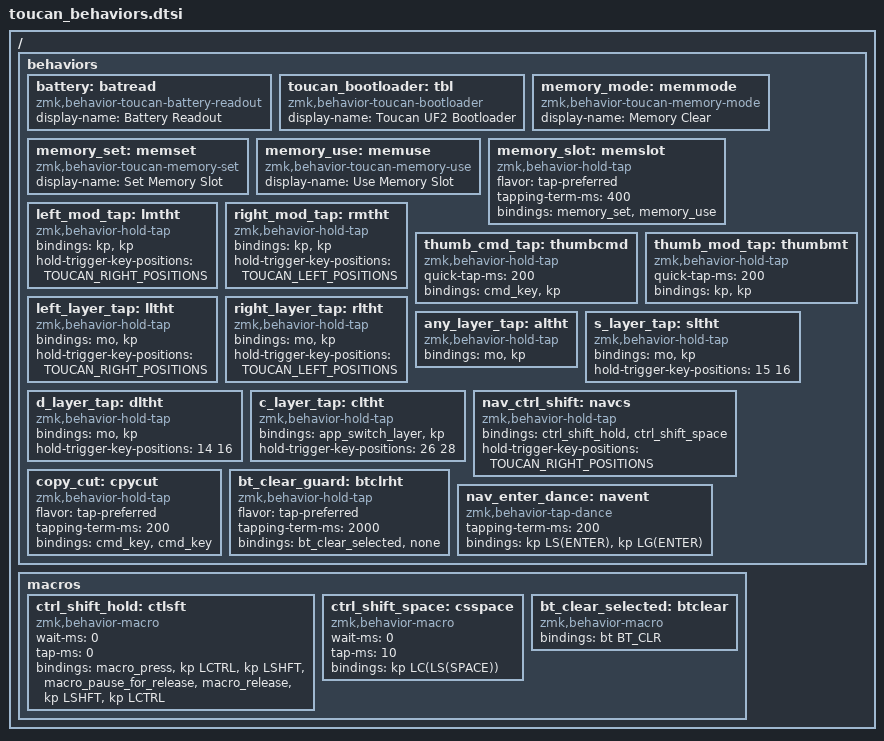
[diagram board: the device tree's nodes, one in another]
/* Custom reusable behaviors shared by both halves. */

#include <toucan_layers.dtsi>

/* One rollover policy for all typing-facing hold-taps, including NAV F.
 * Position filters and thumb repeat are configured per behavior below.
 * Copy/cut, memory replacement, and Bluetooth clear keep deliberate-hold rules. */
#define TOUCAN_TYPING_HOLD_TAP_POLICY                                                           \
    flavor = "balanced";                                                                       \
    tapping-term-ms = <200>;                                                                    \
    require-prior-idle-ms = <125>;

/* Physical positions on the opposite side of each hand's tap-hold keys. */
#define TOUCAN_LEFT_POSITIONS                                                                   \
    0 1 2 3 4 5 12 13 14 15 16 17 24 25 26 27 28 29 36 37 38
#define TOUCAN_RIGHT_POSITIONS                                                                  \
    6 7 8 9 10 11 18 19 20 21 22 23 30 31 32 33 34 35 39 40 41

/ {
    behaviors {
        /* Short node names are required for behaviors used from peripherals. */
        battery: batread {
            compatible = "zmk,behavior-toucan-battery-readout";
            #binding-cells = <0>;
            display-name = "Battery Readout";
        };

        toucan_bootloader: tbl {
            compatible = "zmk,behavior-toucan-bootloader";
            #binding-cells = <0>;
            display-name = "Toucan UF2 Bootloader";
        };

        memory_mode: memmode {
            compatible = "zmk,behavior-toucan-memory-mode";
            #binding-cells = <0>;
            display-name = "Memory Clear";
        };

        memory_set: memset {
            compatible = "zmk,behavior-toucan-memory-set";
            #binding-cells = <1>;
            display-name = "Set Memory Slot";
        };

        memory_use: memuse {
            compatible = "zmk,behavior-toucan-memory-use";
            #binding-cells = <1>;
            display-name = "Use Memory Slot";
        };

        /* Tap a slot to play it; hold it deliberately to replace it. */
        memory_slot: memslot {
            compatible = "zmk,behavior-hold-tap";
            #binding-cells = <2>;
            flavor = "tap-preferred";
            tapping-term-ms = <400>;
            bindings = <&memory_set>, <&memory_use>;
        };

        /* Opposite-hand modifier chords, with the shared typing-roll guard. */
        left_mod_tap: lmtht {
            compatible = "zmk,behavior-hold-tap";
            #binding-cells = <2>;
            TOUCAN_TYPING_HOLD_TAP_POLICY
            bindings = <&kp>, <&kp>;
            hold-trigger-key-positions = <TOUCAN_RIGHT_POSITIONS>;
        };

        right_mod_tap: rmtht {
            compatible = "zmk,behavior-hold-tap";
            #binding-cells = <2>;
            TOUCAN_TYPING_HOLD_TAP_POLICY
            bindings = <&kp>, <&kp>;
            hold-trigger-key-positions = <TOUCAN_LEFT_POSITIONS>;
        };

        /* Tab on tap; platform-aware Command/Control on a deliberate hold. */
        thumb_cmd_tap: thumbcmd {
            compatible = "zmk,behavior-hold-tap";
            #binding-cells = <2>;
            TOUCAN_TYPING_HOLD_TAP_POLICY
            quick-tap-ms = <200>;
            bindings = <&cmd_key>, <&kp>;
        };

        /* Enter on tap; Option/Alt on hold, with tap-then-hold repeat. */
        thumb_mod_tap: thumbmt {
            compatible = "zmk,behavior-hold-tap";
            #binding-cells = <2>;
            TOUCAN_TYPING_HOLD_TAP_POLICY
            quick-tap-ms = <200>;
            bindings = <&kp>, <&kp>;
        };

        /* A and semicolon hold SYM only for opposite-hand chords. */
        left_layer_tap: lltht {
            compatible = "zmk,behavior-hold-tap";
            #binding-cells = <2>;
            TOUCAN_TYPING_HOLD_TAP_POLICY
            bindings = <&mo>, <&kp>;
            hold-trigger-key-positions = <TOUCAN_RIGHT_POSITIONS>;
        };

        right_layer_tap: rltht {
            compatible = "zmk,behavior-hold-tap";
            #binding-cells = <2>;
            TOUCAN_TYPING_HOLD_TAP_POLICY
            bindings = <&mo>, <&kp>;
            hold-trigger-key-positions = <TOUCAN_LEFT_POSITIONS>;
        };

        /* Q and P use release order to distinguish NAV chords from rolls. */
        any_layer_tap: altht {
            compatible = "zmk,behavior-hold-tap";
            #binding-cells = <2>;
            TOUCAN_TYPING_HOLD_TAP_POLICY
            bindings = <&mo>, <&kp>;
        };

        /* S holds CLIP only for D/F; D holds EDIT only for S/F. Release the
         * leader first for a typing roll, or the target first for a chord. */
        s_layer_tap: sltht {
            compatible = "zmk,behavior-hold-tap";
            #binding-cells = <2>;
            TOUCAN_TYPING_HOLD_TAP_POLICY
            bindings = <&mo>, <&kp>;
            hold-trigger-key-positions = <15 16>;
        };

        d_layer_tap: dltht {
            compatible = "zmk,behavior-hold-tap";
            #binding-cells = <2>;
            TOUCAN_TYPING_HOLD_TAP_POLICY
            bindings = <&mo>, <&kp>;
            hold-trigger-key-positions = <14 16>;
        };

        /* C holds APP only for X/V, with the same rollover policy as S/D. */
        c_layer_tap: cltht {
            compatible = "zmk,behavior-hold-tap";
            #binding-cells = <2>;
            TOUCAN_TYPING_HOLD_TAP_POLICY
            bindings = <&app_switch_layer>, <&kp>;
            hold-trigger-key-positions = <26 28>;
        };

        /* NAV F: hold Ctrl+Shift; tap Ctrl+Shift+Space. */
        nav_ctrl_shift: navcs {
            compatible = "zmk,behavior-hold-tap";
            #binding-cells = <2>;
            TOUCAN_TYPING_HOLD_TAP_POLICY
            bindings = <&ctrl_shift_hold>, <&ctrl_shift_space>;
            hold-trigger-key-positions = <TOUCAN_RIGHT_POSITIONS>;
        };

        /* CLIP D: tap/repeat copies; an uninterrupted hold cuts. */
        copy_cut: cpycut {
            compatible = "zmk,behavior-hold-tap";
            #binding-cells = <2>;
            flavor = "tap-preferred";
            tapping-term-ms = <200>;
            bindings = <&cmd_key>, <&cmd_key>;
        };

        /* Releasing before two seconds is inert; holding clears the selected BT profile. */
        bt_clear_guard: btclrht {
            compatible = "zmk,behavior-hold-tap";
            #binding-cells = <2>;
            flavor = "tap-preferred";
            tapping-term-ms = <2000>;
            bindings = <&bt_clear_selected>, <&none>;
        };

        /* NAV D: Shift+Enter once, GUI+Enter twice, matching Moonlander TD1. */
        nav_enter_dance: navent {
            compatible = "zmk,behavior-tap-dance";
            #binding-cells = <0>;
            tapping-term-ms = <200>;
            bindings = <&kp LS(ENTER)>, <&kp LG(ENTER)>;
        };
    };

    macros {
        ctrl_shift_hold: ctlsft {
            compatible = "zmk,behavior-macro";
            #binding-cells = <0>;
            wait-ms = <0>;
            tap-ms = <0>;
            bindings
                = <&macro_press &kp LCTRL &kp LSHFT>
                , <&macro_pause_for_release>
                , <&macro_release &kp LSHFT &kp LCTRL>
                ;
        };

        ctrl_shift_space: csspace {
            compatible = "zmk,behavior-macro";
            #binding-cells = <0>;
            wait-ms = <0>;
            tap-ms = <10>;
            bindings = <&kp LC(LS(SPACE))>;
        };

        bt_clear_selected: btclear {
            compatible = "zmk,behavior-macro";
            #binding-cells = <0>;
            bindings = <&bt BT_CLR>;
        };
    };
};

#undef TOUCAN_TYPING_HOLD_TAP_POLICY
#undef TOUCAN_LEFT_POSITIONS
#undef TOUCAN_RIGHT_POSITIONS
